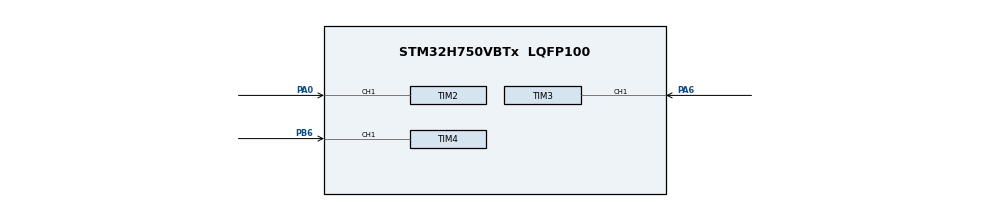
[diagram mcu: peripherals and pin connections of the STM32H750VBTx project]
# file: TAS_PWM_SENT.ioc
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CORTEX_M7.default_mode_Activation=1
Mcu.Family=STM32H7
Mcu.Name=STM32H750VBTx
Mcu.Package=LQFP100
NVIC.PriorityGroup=NVIC_PRIORITYGROUP_4
NVIC.TIM2_IRQn=true\:0\:0\:false\:false\:true\:true\:true\:true
NVIC.TIM3_IRQn=true\:0\:0\:false\:false\:true\:true\:true\:true
NVIC.TIM4_IRQn=true\:0\:0\:false\:false\:true\:true\:true\:true
PA0.Signal=S_TIM2_CH1_ETR
PA6.Signal=S_TIM3_CH1
PB6.Signal=S_TIM4_CH1
ProjectManager.HeapSize=0x200
ProjectManager.StackSize=0x400
ProjectManager.TargetToolchain=STM32CubeIDE
RCC.ADCFreq_Value=129000000
RCC.APB1Freq_Value=64000000
RCC.APB2Freq_Value=64000000
RCC.APB3Freq_Value=64000000
RCC.APB4Freq_Value=64000000
RCC.CortexFreq_Value=64000000
RCC.HCLKFreq_Value=64000000
RCC.SYSCLKFreq_VALUE=64000000
RCC.USBFreq_Value=129000000
SH.S_TIM2_CH1_ETR.0=TIM2_CH1,PWM_Input_1
SH.S_TIM3_CH1.0=TIM3_CH1,PWM_Input_1
SH.S_TIM4_CH1.0=TIM4_CH1,PWM_Input_1
TIM2.ICPolarity_1=TIM_INPUTCHANNELPOLARITY_FALLING
TIM2.Prescaler=63
TIM3.ICPolarity_1=TIM_INPUTCHANNELPOLARITY_FALLING
TIM3.Prescaler=63
TIM4.ICPolarity_1=TIM_INPUTCHANNELPOLARITY_FALLING
VP_MEMORYMAP_VS_MEMORYMAP.Mode=CurAppReg
VP_TIM2_VS_ClockSourceINT.Mode=Internal
VP_TIM3_VS_ClockSourceINT.Mode=Internal
VP_TIM4_VS_ClockSourceINT.Mode=Internal
board=custom

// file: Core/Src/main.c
/* USER CODE BEGIN Header */
/**
  ******************************************************************************
  * @file           : main.c
  * @brief          : Main program body
  ******************************************************************************
  * @attention
  *
  * Copyright (c) 2026 STMicroelectronics.
  * All rights reserved.
  *
  * This software is licensed under terms that can be found in the LICENSE file
  * in the root directory of this software component.
  * If no LICENSE file comes with this software, it is provided AS-IS.
  *
  ******************************************************************************
  */
/* USER CODE END Header */
#include "main.h"

TIM_HandleTypeDef htim2;
TIM_HandleTypeDef htim3;
TIM_HandleTypeDef htim4;

/* USER CODE BEGIN PV */
/* T1 的量測資料 */
volatile uint32_t t1_period_ticks = 0;
volatile uint32_t t1_low_ticks = 0;
volatile uint32_t t1_last_update_ms = 0;
volatile uint32_t t1_age_ms = 0;
volatile uint8_t t1_has_sample = 0;
volatile uint8_t t1_timeout = 0;
volatile uint8_t t1_pwm_format_ok = 0;

/* T2 的量測資料 */
volatile uint32_t t2_period_ticks = 0;
volatile uint32_t t2_low_ticks = 0;
volatile uint32_t t2_last_update_ms = 0;
volatile uint8_t t2_has_sample = 0;
volatile uint8_t t2_pwm_format_ok = 0;
volatile uint8_t t2_timeout = 0;
volatile uint32_t t2_age_ms = 0;
/* USER CODE END PV */

void SystemClock_Config(void);
static void MPU_Config(void);
static void MX_GPIO_Init(void);
static void MX_TIM2_Init(void);
static void MX_TIM3_Init(void);
static void MX_TIM4_Init(void);

int main(void)
{

  /* MPU Configuration--------------------------------------------------------*/
  MPU_Config();

  /* MCU Configuration--------------------------------------------------------*/

  /* Reset of all peripherals, Initializes the Flash interface and the Systick. */
  HAL_Init();

  /* Configure the system clock */
  SystemClock_Config();

  /* Initialize all configured peripherals */
  MX_GPIO_Init();
  MX_TIM2_Init();
  MX_TIM3_Init();
  MX_TIM4_Init();
  /* USER CODE BEGIN 2 */

  /* 先啟用 CH2，擷取低電位時間 */
  if (HAL_TIM_IC_Start(&htim2, TIM_CHANNEL_2) != HAL_OK)
  {
    Error_Handler();
  }

  /* 再啟用 CH1，擷取週期並產生中斷 */
  if (HAL_TIM_IC_Start_IT(&htim2, TIM_CHANNEL_1) != HAL_OK)
  {
    Error_Handler();
  }

  /* T2：先啟用 CH2，擷取低電位時間 */
  if (HAL_TIM_IC_Start(&htim3, TIM_CHANNEL_2) != HAL_OK)
  {
      Error_Handler();
  }

  /* T2：啟用 CH1，擷取週期並產生中斷 */
  if (HAL_TIM_IC_Start_IT(&htim3, TIM_CHANNEL_1) != HAL_OK)
  {
      Error_Handler();
  }
  /* USER CODE END 2 */

  /* Infinite loop */
  while (1)
  {

    /* USER CODE BEGIN 3 */

	uint8_t result = CheckT1Pwm(0, 0);

	if (t1_has_sample == 1)
	{

	    uint32_t last_update = t1_last_update_ms;
	    uint32_t now = HAL_GetTick();

	    t1_age_ms = now - last_update;

	    if (t1_age_ms >= 5U)
		{
			t1_timeout = 1;
		}
		else
		{
			t1_timeout = 0;
		}

	}

	else if(t2_has_sample == 1)
	{
		uint32_t last_update = t2_last_update_ms;
		uint32_t now = HAL_GetTick();

		t2_age_ms = now - last_update;

		if (t2_age_ms >= 5U)
		{
			t2_timeout = 1;

		}
		else
		{
			t2_timeout = 0;
		}
	}

	else
	{
	    /* 尚未收到資料，暫不計算資料年齡 */
	    t1_age_ms = 0;
	    t1_timeout = 0;

	    t2_age_ms = 0;
	    t2_timeout = 0;

	}

  }
  /* USER CODE END 3 */
}

void SystemClock_Config(void)
{
  RCC_OscInitTypeDef RCC_OscInitStruct = {0};
  RCC_ClkInitTypeDef RCC_ClkInitStruct = {0};

  /** Supply configuration update enable
  */
  HAL_PWREx_ConfigSupply(PWR_LDO_SUPPLY);

  /** Configure the main internal regulator output voltage
  */
  __HAL_PWR_VOLTAGESCALING_CONFIG(PWR_REGULATOR_VOLTAGE_SCALE3);

  while(!__HAL_PWR_GET_FLAG(PWR_FLAG_VOSRDY)) {}

  /** Initializes the RCC Oscillators according to the specified parameters
  * in the RCC_OscInitTypeDef structure.
  */
  RCC_OscInitStruct.OscillatorType = RCC_OSCILLATORTYPE_HSI;
  RCC_OscInitStruct.HSIState = RCC_HSI_DIV1;
  RCC_OscInitStruct.HSICalibrationValue = RCC_HSICALIBRATION_DEFAULT;
  RCC_OscInitStruct.PLL.PLLState = RCC_PLL_NONE;
  if (HAL_RCC_OscConfig(&RCC_OscInitStruct) != HAL_OK)
  {
    Error_Handler();
  }

  /** Initializes the CPU, AHB and APB buses clocks
  */
  RCC_ClkInitStruct.ClockType = RCC_CLOCKTYPE_HCLK|RCC_CLOCKTYPE_SYSCLK
                              |RCC_CLOCKTYPE_PCLK1|RCC_CLOCKTYPE_PCLK2
                              |RCC_CLOCKTYPE_D3PCLK1|RCC_CLOCKTYPE_D1PCLK1;
  RCC_ClkInitStruct.SYSCLKSource = RCC_SYSCLKSOURCE_HSI;
  RCC_ClkInitStruct.SYSCLKDivider = RCC_SYSCLK_DIV1;
  RCC_ClkInitStruct.AHBCLKDivider = RCC_HCLK_DIV1;
  RCC_ClkInitStruct.APB3CLKDivider = RCC_APB3_DIV1;
  RCC_ClkInitStruct.APB1CLKDivider = RCC_APB1_DIV1;
  RCC_ClkInitStruct.APB2CLKDivider = RCC_APB2_DIV1;
  RCC_ClkInitStruct.APB4CLKDivider = RCC_APB4_DIV1;

  if (HAL_RCC_ClockConfig(&RCC_ClkInitStruct, FLASH_LATENCY_1) != HAL_OK)
  {
    Error_Handler();
  }
}

static void MX_TIM2_Init(void)
{

  TIM_ClockConfigTypeDef sClockSourceConfig = {0};
  TIM_SlaveConfigTypeDef sSlaveConfig = {0};
  TIM_IC_InitTypeDef sConfigIC = {0};
  TIM_MasterConfigTypeDef sMasterConfig = {0};

  htim2.Instance = TIM2;
  htim2.Init.Prescaler = 63;
  htim2.Init.CounterMode = TIM_COUNTERMODE_UP;
  htim2.Init.Period = 4294967295;
  htim2.Init.ClockDivision = TIM_CLOCKDIVISION_DIV1;
  htim2.Init.AutoReloadPreload = TIM_AUTORELOAD_PRELOAD_DISABLE;
  if (HAL_TIM_Base_Init(&htim2) != HAL_OK)
  {
    Error_Handler();
  }
  sClockSourceConfig.ClockSource = TIM_CLOCKSOURCE_INTERNAL;
  if (HAL_TIM_ConfigClockSource(&htim2, &sClockSourceConfig) != HAL_OK)
  {
    Error_Handler();
  }
  if (HAL_TIM_IC_Init(&htim2) != HAL_OK)
  {
    Error_Handler();
  }
  sSlaveConfig.SlaveMode = TIM_SLAVEMODE_RESET;
  sSlaveConfig.InputTrigger = TIM_TS_TI1FP1;
  sSlaveConfig.TriggerPolarity = TIM_INPUTCHANNELPOLARITY_FALLING;
  sSlaveConfig.TriggerPrescaler = TIM_ICPSC_DIV1;
  sSlaveConfig.TriggerFilter = 0;
  if (HAL_TIM_SlaveConfigSynchro(&htim2, &sSlaveConfig) != HAL_OK)
  {
    Error_Handler();
  }
  sConfigIC.ICPolarity = TIM_INPUTCHANNELPOLARITY_FALLING;
  sConfigIC.ICSelection = TIM_ICSELECTION_DIRECTTI;
  sConfigIC.ICPrescaler = TIM_ICPSC_DIV1;
  sConfigIC.ICFilter = 0;
  if (HAL_TIM_IC_ConfigChannel(&htim2, &sConfigIC, TIM_CHANNEL_1) != HAL_OK)
  {
    Error_Handler();
  }
  sConfigIC.ICPolarity = TIM_INPUTCHANNELPOLARITY_RISING;
  sConfigIC.ICSelection = TIM_ICSELECTION_INDIRECTTI;
  if (HAL_TIM_IC_ConfigChannel(&htim2, &sConfigIC, TIM_CHANNEL_2) != HAL_OK)
  {
    Error_Handler();
  }
  sMasterConfig.MasterOutputTrigger = TIM_TRGO_RESET;
  sMasterConfig.MasterSlaveMode = TIM_MASTERSLAVEMODE_DISABLE;
  if (HAL_TIMEx_MasterConfigSynchronization(&htim2, &sMasterConfig) != HAL_OK)
  {
    Error_Handler();
  }

}

static void MX_TIM3_Init(void)
{

  TIM_ClockConfigTypeDef sClockSourceConfig = {0};
  TIM_SlaveConfigTypeDef sSlaveConfig = {0};
  TIM_IC_InitTypeDef sConfigIC = {0};
  TIM_MasterConfigTypeDef sMasterConfig = {0};

  htim3.Instance = TIM3;
  htim3.Init.Prescaler = 63;
  htim3.Init.CounterMode = TIM_COUNTERMODE_UP;
  htim3.Init.Period = 65535;
  htim3.Init.ClockDivision = TIM_CLOCKDIVISION_DIV1;
  htim3.Init.AutoReloadPreload = TIM_AUTORELOAD_PRELOAD_DISABLE;
  if (HAL_TIM_Base_Init(&htim3) != HAL_OK)
  {
    Error_Handler();
  }
  sClockSourceConfig.ClockSource = TIM_CLOCKSOURCE_INTERNAL;
  if (HAL_TIM_ConfigClockSource(&htim3, &sClockSourceConfig) != HAL_OK)
  {
    Error_Handler();
  }
  if (HAL_TIM_IC_Init(&htim3) != HAL_OK)
  {
    Error_Handler();
  }
  sSlaveConfig.SlaveMode = TIM_SLAVEMODE_RESET;
  sSlaveConfig.InputTrigger = TIM_TS_TI1FP1;
  sSlaveConfig.TriggerPolarity = TIM_INPUTCHANNELPOLARITY_FALLING;
  sSlaveConfig.TriggerPrescaler = TIM_ICPSC_DIV1;
  sSlaveConfig.TriggerFilter = 0;
  if (HAL_TIM_SlaveConfigSynchro(&htim3, &sSlaveConfig) != HAL_OK)
  {
    Error_Handler();
  }
  sConfigIC.ICPolarity = TIM_INPUTCHANNELPOLARITY_FALLING;
  sConfigIC.ICSelection = TIM_ICSELECTION_DIRECTTI;
  sConfigIC.ICPrescaler = TIM_ICPSC_DIV1;
  sConfigIC.ICFilter = 0;
  if (HAL_TIM_IC_ConfigChannel(&htim3, &sConfigIC, TIM_CHANNEL_1) != HAL_OK)
  {
    Error_Handler();
  }
  sConfigIC.ICPolarity = TIM_INPUTCHANNELPOLARITY_RISING;
  sConfigIC.ICSelection = TIM_ICSELECTION_INDIRECTTI;
  if (HAL_TIM_IC_ConfigChannel(&htim3, &sConfigIC, TIM_CHANNEL_2) != HAL_OK)
  {
    Error_Handler();
  }
  sMasterConfig.MasterOutputTrigger = TIM_TRGO_RESET;
  sMasterConfig.MasterSlaveMode = TIM_MASTERSLAVEMODE_DISABLE;
  if (HAL_TIMEx_MasterConfigSynchronization(&htim3, &sMasterConfig) != HAL_OK)
  {
    Error_Handler();
  }

}

static void MX_TIM4_Init(void)
{

  TIM_ClockConfigTypeDef sClockSourceConfig = {0};
  TIM_SlaveConfigTypeDef sSlaveConfig = {0};
  TIM_IC_InitTypeDef sConfigIC = {0};
  TIM_MasterConfigTypeDef sMasterConfig = {0};

  htim4.Instance = TIM4;
  htim4.Init.Prescaler = 0;
  htim4.Init.CounterMode = TIM_COUNTERMODE_UP;
  htim4.Init.Period = 65535;
  htim4.Init.ClockDivision = TIM_CLOCKDIVISION_DIV1;
  htim4.Init.AutoReloadPreload = TIM_AUTORELOAD_PRELOAD_DISABLE;
  if (HAL_TIM_Base_Init(&htim4) != HAL_OK)
  {
    Error_Handler();
  }
  sClockSourceConfig.ClockSource = TIM_CLOCKSOURCE_INTERNAL;
  if (HAL_TIM_ConfigClockSource(&htim4, &sClockSourceConfig) != HAL_OK)
  {
    Error_Handler();
  }
  if (HAL_TIM_IC_Init(&htim4) != HAL_OK)
  {
    Error_Handler();
  }
  sSlaveConfig.SlaveMode = TIM_SLAVEMODE_RESET;
  sSlaveConfig.InputTrigger = TIM_TS_TI1FP1;
  sSlaveConfig.TriggerPolarity = TIM_INPUTCHANNELPOLARITY_FALLING;
  sSlaveConfig.TriggerPrescaler = TIM_ICPSC_DIV1;
  sSlaveConfig.TriggerFilter = 0;
  if (HAL_TIM_SlaveConfigSynchro(&htim4, &sSlaveConfig) != HAL_OK)
  {
    Error_Handler();
  }
  sConfigIC.ICPolarity = TIM_INPUTCHANNELPOLARITY_FALLING;
  sConfigIC.ICSelection = TIM_ICSELECTION_DIRECTTI;
  sConfigIC.ICPrescaler = TIM_ICPSC_DIV1;
  sConfigIC.ICFilter = 0;
  if (HAL_TIM_IC_ConfigChannel(&htim4, &sConfigIC, TIM_CHANNEL_1) != HAL_OK)
  {
    Error_Handler();
  }
  sConfigIC.ICPolarity = TIM_INPUTCHANNELPOLARITY_RISING;
  sConfigIC.ICSelection = TIM_ICSELECTION_INDIRECTTI;
  if (HAL_TIM_IC_ConfigChannel(&htim4, &sConfigIC, TIM_CHANNEL_2) != HAL_OK)
  {
    Error_Handler();
  }
  sMasterConfig.MasterOutputTrigger = TIM_TRGO_RESET;
  sMasterConfig.MasterSlaveMode = TIM_MASTERSLAVEMODE_DISABLE;
  if (HAL_TIMEx_MasterConfigSynchronization(&htim4, &sMasterConfig) != HAL_OK)
  {
    Error_Handler();
  }

}

static void MX_GPIO_Init(void)
{

  /* GPIO Ports Clock Enable */
  __HAL_RCC_GPIOA_CLK_ENABLE();
  __HAL_RCC_GPIOB_CLK_ENABLE();

}

/* USER CODE BEGIN 4 */
void HAL_TIM_IC_CaptureCallback(TIM_HandleTypeDef *htim)
{

  static uint8_t first_capture = 1;
  static uint8_t t2_first_capture = 1;

  if (htim->Instance == TIM2 && htim->Channel == HAL_TIM_ACTIVE_CHANNEL_1)
  {
    /* 第一筆可能不完整，先捨棄 */
    if (first_capture)
    {
      first_capture = 0;
      return;
    }

    t1_pwm_format_ok = 0;
    t1_period_ticks = HAL_TIM_ReadCapturedValue(htim, TIM_CHANNEL_1);
    t1_low_ticks = HAL_TIM_ReadCapturedValue(htim, TIM_CHANNEL_2);
    t1_last_update_ms = HAL_GetTick();
    t1_has_sample = 1; //Handle null

    if ((t1_period_ticks > 0) && (t1_low_ticks <= t1_period_ticks))
    {

    	float frequency_hz = 1000000.0f / t1_period_ticks;  //TIM2 Input clock：64 MHz

    	float duty_percent = 100.0f * t1_low_ticks / t1_period_ticks;

    	if((duty_percent >= 6.25f) && (duty_percent <= 93.75f) && (frequency_hz >= 1700.0f) && (frequency_hz <= 2300.0f)){

    		t1_pwm_format_ok = 1;
    	}

    }

  }

  else if(htim->Instance == TIM3 && htim->Channel == HAL_TIM_ACTIVE_CHANNEL_1)
  {

	  if (t2_first_capture)
	  {
		  t2_first_capture = 0;
		  return;
	  }

	  t2_period_ticks = HAL_TIM_ReadCapturedValue(htim, TIM_CHANNEL_1);
	  t2_low_ticks = HAL_TIM_ReadCapturedValue(htim, TIM_CHANNEL_2);
	  t2_last_update_ms = HAL_GetTick();
	  t2_has_sample = 1;
	  t2_pwm_format_ok = 0;

	  float duty_percent = 100.0f * t2_low_ticks / t2_period_ticks;
	  float frequency_hz = 1000000.0f / t2_period_ticks;  //TIM3 Input clock：64 MHz

	  t2_last_update_ms = HAL_GetTick();

	  if((t2_period_ticks > 0) && (t2_low_ticks <= t2_period_ticks))
	  {

		  if((duty_percent >= 6.25f) && (duty_percent <= 93.75f) && (frequency_hz >= 1700.0f) && (frequency_hz <= 2300.0f)){

		      t2_pwm_format_ok = 1;
		  }
	  }
  }

}

uint8_t CheckT1Pwm(uint32_t period_ticks,uint32_t low_ticks)
{

	if (period_ticks == 0)

	{
		return 0;
	}
	if (low_ticks > period_ticks)
	{
	    return 0;
	}

	/* 其他檢查尚未加入，目前先回傳不通過 */
	return 0;
}
/* USER CODE END 4 */

 /* MPU Configuration */

void MPU_Config(void)
{
  MPU_Region_InitTypeDef MPU_InitStruct = {0};

  /* Disables the MPU */
  HAL_MPU_Disable();

  /** Initializes and configures the Region and the memory to be protected
  */
  MPU_InitStruct.Enable = MPU_REGION_ENABLE;
  MPU_InitStruct.Number = MPU_REGION_NUMBER0;
  MPU_InitStruct.BaseAddress = 0x0;
  MPU_InitStruct.Size = MPU_REGION_SIZE_4GB;
  MPU_InitStruct.SubRegionDisable = 0x87;
  MPU_InitStruct.TypeExtField = MPU_TEX_LEVEL0;
  MPU_InitStruct.AccessPermission = MPU_REGION_NO_ACCESS;
  MPU_InitStruct.DisableExec = MPU_INSTRUCTION_ACCESS_DISABLE;
  MPU_InitStruct.IsShareable = MPU_ACCESS_SHAREABLE;
  MPU_InitStruct.IsCacheable = MPU_ACCESS_NOT_CACHEABLE;
  MPU_InitStruct.IsBufferable = MPU_ACCESS_NOT_BUFFERABLE;

  HAL_MPU_ConfigRegion(&MPU_InitStruct);
  /* Enables the MPU */
  HAL_MPU_Enable(MPU_PRIVILEGED_DEFAULT);

}

void Error_Handler(void)
{
  __disable_irq();
  while (1)
  {
  }
}
